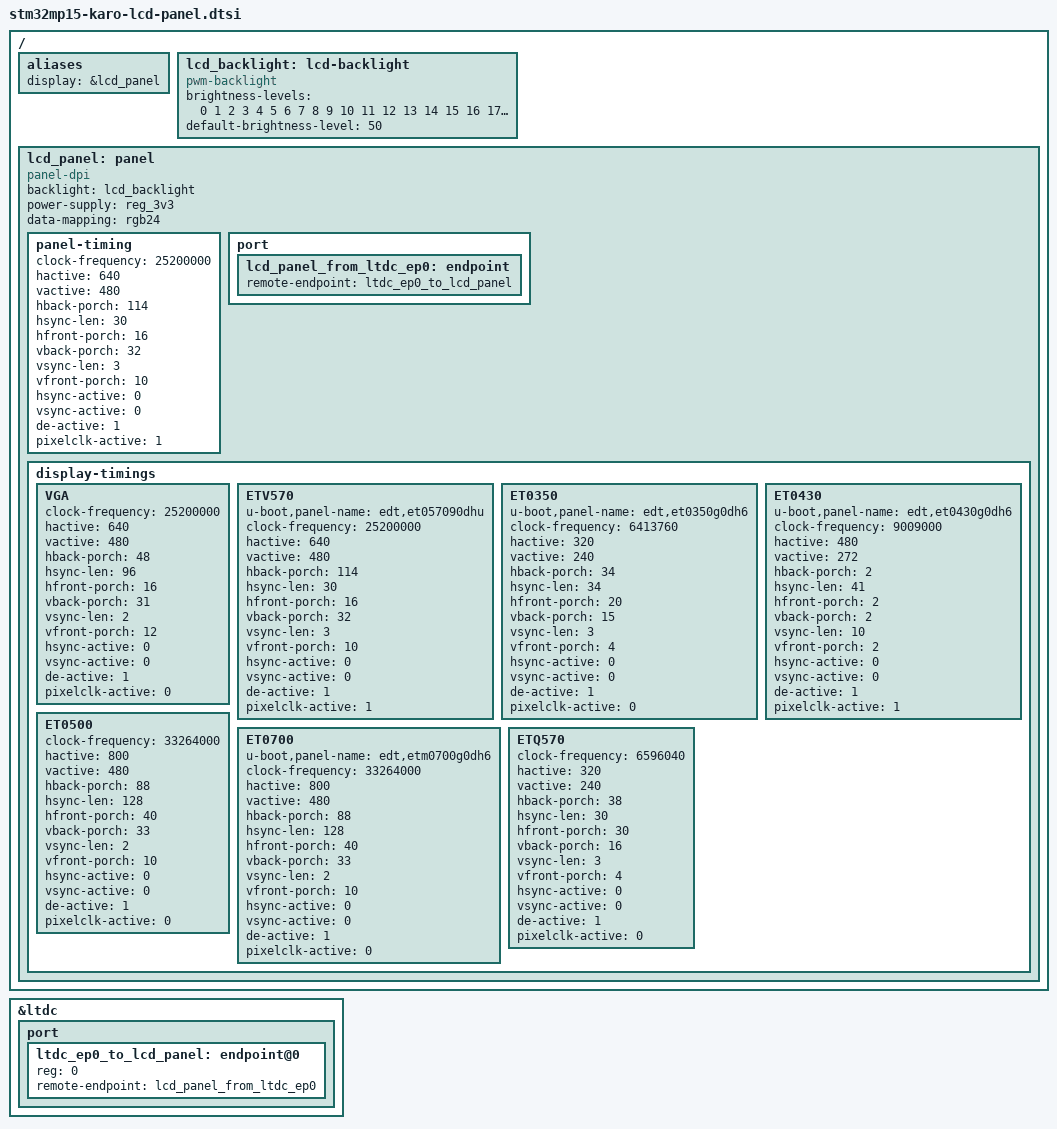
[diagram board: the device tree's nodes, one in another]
// SPDX-License-Identifier: GPL-2.0 OR BSD-3-Clause
/*
 * Copyright (C) 2020 Lothar Waßmann <LW@KARO-electronics.de>
 */

/ {
	aliases {
		display = &lcd_panel;
	};

	lcd_backlight: lcd-backlight {
		compatible = "pwm-backlight";
		pinctrl-names = "default", "sleep";
		brightness-levels = <0 1  2  3  4  5  6  7  8  9  10
				     11 12 13 14 15 16 17 18 19  20
				     21 22 23 24 25 26 27 28 29  30
				     31 32 33 34 35 36 37 38 39  40
				     41 42 43 44 45 46 47 48 49  50
				     51 52 53 54 55 56 57 58 59  60
				     61 62 63 64 65 66 67 68 69  70
				     71 72 73 74 75 76 77 78 79  80
				     81 82 83 84 85 86 87 88 89  90
				     91 92 93 94 95 96 97 98 99 100
				    >;
		default-brightness-level = <50>;
	};

	lcd_panel: panel {
		compatible = "panel-dpi";
		backlight = <&lcd_backlight>;
		power-supply = <&reg_3v3>;
		data-mapping = "rgb24";
		status = "okay";

		panel-timing {
			clock-frequency = <25200000>;
			hactive = <640>;
			vactive = <480>;
			hback-porch = <114>;
			hsync-len = <30>;
			hfront-porch = <16>;
			vback-porch = <32>;
			vsync-len = <3>;
			vfront-porch = <10>;
			hsync-active = <0>;
			vsync-active = <0>;
			de-active = <1>;
			pixelclk-active = <1>;
		};

		port {
			lcd_panel_from_ltdc_ep0: endpoint {
				remote-endpoint = <&ltdc_ep0_to_lcd_panel>;
			};
		};

		display-timings {
			VGA: VGA {
				clock-frequency = <25200000>;
				hactive = <640>;
				vactive = <480>;
				hback-porch = <48>;
				hsync-len = <96>;
				hfront-porch = <16>;
				vback-porch = <31>;
				vsync-len = <2>;
				vfront-porch = <12>;
				hsync-active = <0>;
				vsync-active = <0>;
				de-active = <1>;
				pixelclk-active = <0>;
			};

			ETV570: ETV570 {
				u-boot,panel-name = "edt,et057090dhu";
				clock-frequency = <25200000>;
				hactive = <640>;
				vactive = <480>;
				hback-porch = <114>;
				hsync-len = <30>;
				hfront-porch = <16>;
				vback-porch = <32>;
				vsync-len = <3>;
				vfront-porch = <10>;
				hsync-active = <0>;
				vsync-active = <0>;
				de-active = <1>;
				pixelclk-active = <1>;
			};

			ET0350: ET0350 {
				u-boot,panel-name = "edt,et0350g0dh6";
				clock-frequency = <6413760>;
				hactive = <320>;
				vactive = <240>;
				hback-porch = <34>;
				hsync-len = <34>;
				hfront-porch = <20>;
				vback-porch = <15>;
				vsync-len = <3>;
				vfront-porch = <4>;
				hsync-active = <0>;
				vsync-active = <0>;
				de-active = <1>;
				pixelclk-active = <0>;
			};

			ET0430: ET0430 {
				u-boot,panel-name = "edt,et0430g0dh6";
				clock-frequency = <9009000>;
				hactive = <480>;
				vactive = <272>;
				hback-porch = <2>;
				hsync-len = <41>;
				hfront-porch = <2>;
				vback-porch = <2>;
				vsync-len = <10>;
				vfront-porch = <2>;
				hsync-active = <0>;
				vsync-active = <0>;
				de-active = <1>;
				pixelclk-active = <1>;
			};

			ET0500: ET0500 {
				clock-frequency = <33264000>;
				hactive = <800>;
				vactive = <480>;
				hback-porch = <88>;
				hsync-len = <128>;
				hfront-porch = <40>;
				vback-porch = <33>;
				vsync-len = <2>;
				vfront-porch = <10>;
				hsync-active = <0>;
				vsync-active = <0>;
				de-active = <1>;
				pixelclk-active = <0>;
			};

			ET0700: ET0700 { /* same as ET0500 */
				u-boot,panel-name = "edt,etm0700g0dh6";
				clock-frequency = <33264000>;
				hactive = <800>;
				vactive = <480>;
				hback-porch = <88>;
				hsync-len = <128>;
				hfront-porch = <40>;
				vback-porch = <33>;
				vsync-len = <2>;
				vfront-porch = <10>;
				hsync-active = <0>;
				vsync-active = <0>;
				de-active = <1>;
				pixelclk-active = <0>;
			};

			ETQ570: ETQ570 {
				clock-frequency = <6596040>;
				hactive = <320>;
				vactive = <240>;
				hback-porch = <38>;
				hsync-len = <30>;
				hfront-porch = <30>;
				vback-porch = <16>;
				vsync-len = <3>;
				vfront-porch = <4>;
				hsync-active = <0>;
				vsync-active = <0>;
				de-active = <1>;
				pixelclk-active = <0>;
			};
		};
	};
};

&ltdc {
	status = "okay";

	port {
		ltdc_ep0_to_lcd_panel: endpoint@0 {
			reg = <0>;
			remote-endpoint = <&lcd_panel_from_ltdc_ep0>;
		};
	};
};
